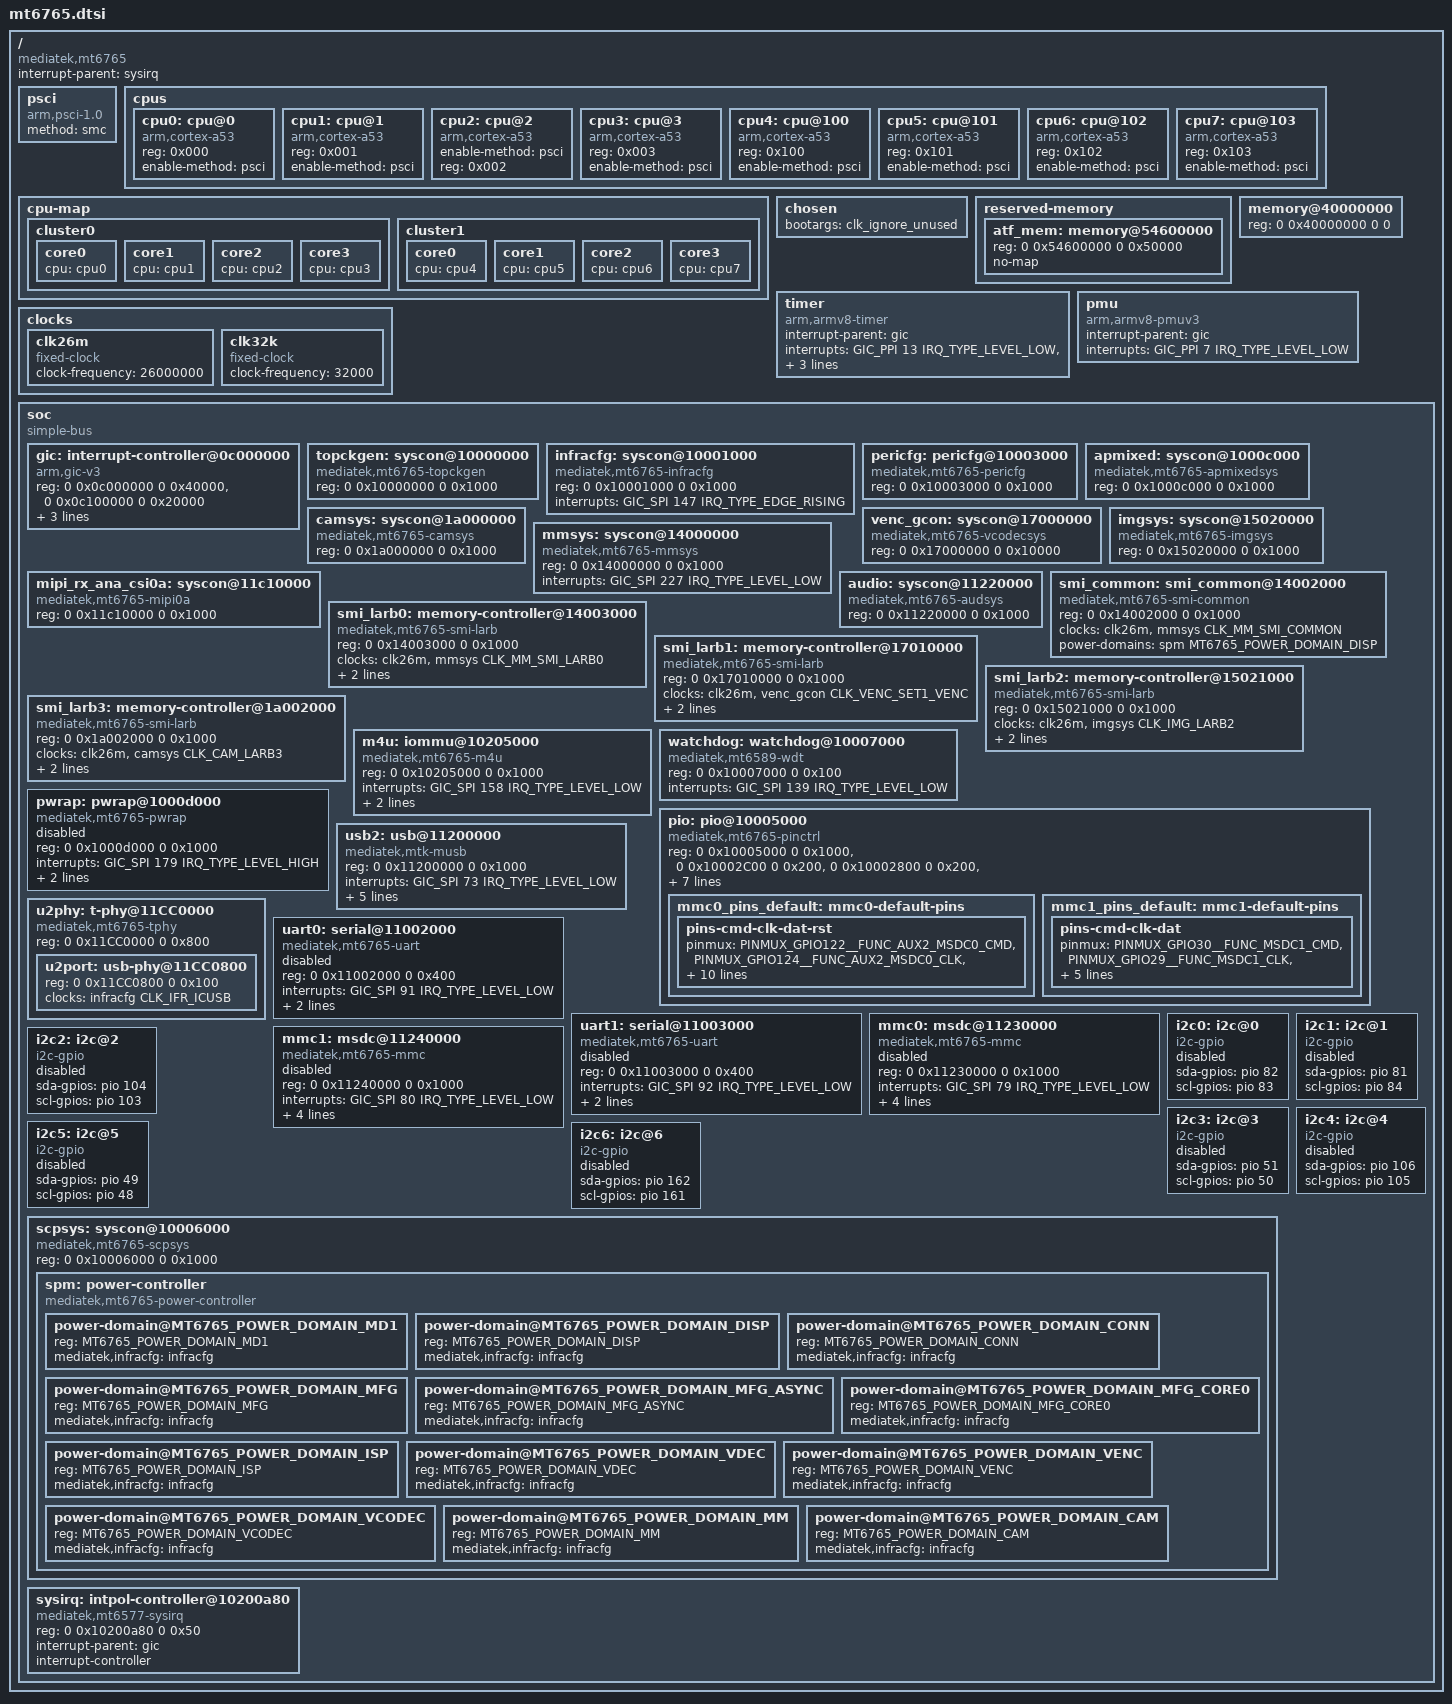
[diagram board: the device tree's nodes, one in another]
// SPDX-License-Identifier: GPL-2.0
/*
 * Copyright (c) 2023 Arseniy Velikanov <adomerlee@gmail.com>
 */

#include <dt-bindings/interrupt-controller/irq.h>
#include <dt-bindings/interrupt-controller/arm-gic.h>
#include <dt-bindings/clock/mt6765-clk.h>
#include <dt-bindings/gpio/gpio.h>
#include <dt-bindings/phy/phy.h>
#include <dt-bindings/power/mt6765-power.h>
#include <dt-bindings/pinctrl/mediatek,mt6765-pinfunc.h>

/ {
    compatible = "mediatek,mt6765";
    interrupt-parent = <&sysirq>;
    #address-cells = <2>;
    #size-cells = <2>;

    psci {
        compatible = "arm,psci-1.0";
        method = "smc";
    };

    cpus {
        #address-cells = <1>;
        #size-cells = <0>;

        cpu0: cpu@0 {
            device_type = "cpu";
            compatible = "arm,cortex-a53";
	        reg = <0x000>;
            enable-method = "psci";
        };

        cpu1: cpu@1 {
            device_type = "cpu";
            compatible = "arm,cortex-a53";
	        reg = <0x001>;
            enable-method = "psci";
        };

        cpu2: cpu@2 {
            device_type = "cpu";
            compatible = "arm,cortex-a53";
            enable-method = "psci";
            reg = <0x002>;
        };

        cpu3: cpu@3 {
            device_type = "cpu";
            compatible = "arm,cortex-a53";
	        reg = <0x003>;
            enable-method = "psci";
        };

        cpu4: cpu@100 {
            device_type = "cpu";
            compatible = "arm,cortex-a53";
	        reg = <0x100>;
            enable-method = "psci";
        };

        cpu5: cpu@101 {
            device_type = "cpu";
            compatible = "arm,cortex-a53";
	        reg = <0x101>;
            enable-method = "psci";
        };

        cpu6: cpu@102 {
            device_type = "cpu";
            compatible = "arm,cortex-a53";
	        reg = <0x102>;
            enable-method = "psci";
        };

        cpu7: cpu@103 {
            device_type = "cpu";
            compatible = "arm,cortex-a53";
	        reg = <0x103>;
            enable-method = "psci";
        };
    };

    cpu-map {
        cluster0 {
            core0 {
                cpu = <&cpu0>;
            };
            core1 {
                cpu = <&cpu1>;
            };
            core2 {
                cpu = <&cpu2>;
            };
            core3 {
                cpu = <&cpu3>;
            };
        };

        cluster1 {
            core0 {
                cpu = <&cpu4>;
            };
            core1 {
                cpu = <&cpu5>;
            };
            core2 {
                cpu = <&cpu6>;
            };
            core3 {
                cpu = <&cpu7>;
            };
        };
    };

    chosen {
        #address-cells = <2>;
        #size-cells = <2>;
        ranges;

        /*
         * FIXME: drop clk_ignore_unused, keeps getting watchdog rebooted without it for now!
         */
        bootargs = "clk_ignore_unused";
    };

    reserved-memory {
        #address-cells = <2>;
        #size-cells = <2>;
        ranges;

        atf_mem: memory@54600000 {
            reg = <0 0x54600000 0 0x50000>;
            no-map;
        };
    };

    memory@40000000 {
        device_type = "memory";
        /* We expect the bootloader to fill in the reg */
        reg = <0 0x40000000 0 0>;
    };

    timer {
        compatible = "arm,armv8-timer";
        interrupt-parent = <&gic>;
        interrupts = <GIC_PPI 13 IRQ_TYPE_LEVEL_LOW>,
                     <GIC_PPI 14 IRQ_TYPE_LEVEL_LOW>,
                     <GIC_PPI 11 IRQ_TYPE_LEVEL_LOW>,
                     <GIC_PPI 10 IRQ_TYPE_LEVEL_LOW>;
    };

    pmu {
        compatible = "arm,armv8-pmuv3";
        interrupt-parent = <&gic>;
        interrupts = <GIC_PPI 7 IRQ_TYPE_LEVEL_LOW>;
    };

    clocks {
        clk26m: clk26m {
            compatible = "fixed-clock";
            #clock-cells = <0>;
            clock-frequency = <26000000>;
        };

        clk32k: clk32k {
            compatible = "fixed-clock";
            #clock-cells = <0>;
            clock-frequency = <32000>;
        };
    };

    soc {
        #address-cells = <2>;
        #size-cells = <2>;
        compatible = "simple-bus";
        ranges;

        gic: interrupt-controller@0c000000 {
            compatible = "arm,gic-v3";
            reg = <0 0x0c000000 0 0x40000>,  /* GICD */
                  <0 0x0c100000 0 0x20000>;  /* GICR */
            #interrupt-cells = <3>;
            interrupt-parent = <&gic>;
            interrupts = <GIC_PPI 9 IRQ_TYPE_LEVEL_HIGH>;
            interrupt-controller;
        };

        topckgen: syscon@10000000 {
            compatible = "mediatek,mt6765-topckgen", "syscon";
            reg = <0 0x10000000 0 0x1000>;
            #clock-cells = <1>;
        };

        infracfg: syscon@10001000 {
            compatible = "mediatek,mt6765-infracfg", "syscon";
            reg = <0 0x10001000 0 0x1000>;
            interrupts = <GIC_SPI 147 IRQ_TYPE_EDGE_RISING>;
            #clock-cells = <1>;
        };

        pericfg: pericfg@10003000 {
            compatible = "mediatek,mt6765-pericfg", "syscon";
            reg = <0 0x10003000 0 0x1000>;
        };

        apmixed: syscon@1000c000 {
            compatible = "mediatek,mt6765-apmixedsys", "syscon";
            reg = <0 0x1000c000 0 0x1000>;
            #clock-cells = <1>;
        };

        camsys: syscon@1a000000  {
            compatible = "mediatek,mt6765-camsys", "syscon";
            reg = <0 0x1a000000 0 0x1000>;
            #clock-cells = <1>;
        };

        venc_gcon: syscon@17000000 {
            compatible = "mediatek,mt6765-vcodecsys", "syscon";
            reg = <0 0x17000000 0 0x10000>;
            #clock-cells = <1>;
        };

        imgsys: syscon@15020000 {
            compatible = "mediatek,mt6765-imgsys", "syscon";
            reg = <0 0x15020000 0 0x1000>;
            #clock-cells = <1>;
        };

        mmsys: syscon@14000000 {
            compatible = "mediatek,mt6765-mmsys", "syscon";
            reg = <0 0x14000000 0 0x1000>;
            interrupts = <GIC_SPI 227 IRQ_TYPE_LEVEL_LOW>;
            #clock-cells = <1>;
        };

        mipi_rx_ana_csi0a: syscon@11c10000 {
            compatible = "mediatek,mt6765-mipi0a", "syscon";
            reg = <0 0x11c10000 0 0x1000>;
            #clock-cells = <1>;
        };

        audio: syscon@11220000 {
            compatible = "mediatek,mt6765-audsys", "syscon";
            reg = <0 0x11220000 0 0x1000>;
            #clock-cells = <1>;
        };

        smi_common: smi_common@14002000 {
            compatible = "mediatek,mt6765-smi-common";
            reg = <0 0x14002000 0 0x1000>;
            clocks = <&clk26m>,
                     <&mmsys CLK_MM_SMI_COMMON>;
            clock-names = "apb", "smi";

            power-domains = <&spm MT6765_POWER_DOMAIN_DISP>;

        };

        smi_larb0: memory-controller@14003000 {
            compatible = "mediatek,mt6765-smi-larb";
            reg = <0 0x14003000 0 0x1000>;

            clocks = <&clk26m>,
                     <&mmsys CLK_MM_SMI_LARB0>;
            clock-names = "apb", "smi";

            power-domains = <&spm MT6765_POWER_DOMAIN_DISP>;

            mediatek,smi = <&smi_common>;
        };

        smi_larb1: memory-controller@17010000 {
            compatible = "mediatek,mt6765-smi-larb";
            reg = <0 0x17010000 0 0x1000>;

            clocks = <&clk26m>,
                     <&venc_gcon CLK_VENC_SET1_VENC>;
            clock-names = "apb", "smi";

            power-domains = <&spm MT6765_POWER_DOMAIN_VCODEC>;

            mediatek,smi = <&smi_common>;
        };

        smi_larb2: memory-controller@15021000 {
            compatible = "mediatek,mt6765-smi-larb";
            reg = <0 0x15021000 0 0x1000>;

            clocks = <&clk26m>,
                     <&imgsys CLK_IMG_LARB2>;
            clock-names = "apb", "smi";

            power-domains = <&spm MT6765_POWER_DOMAIN_ISP>;

            mediatek,smi = <&smi_common>;
        };

        smi_larb3: memory-controller@1a002000 {
            compatible = "mediatek,mt6765-smi-larb";
            reg = <0 0x1a002000 0 0x1000>;

            clocks = <&clk26m>,
                     <&camsys CLK_CAM_LARB3>;
            clock-names = "apb", "smi";

            power-domains = <&spm MT6765_POWER_DOMAIN_CAM>;

            mediatek,smi = <&smi_common>;
        };

        m4u: iommu@10205000 {
            compatible = "mediatek,mt6765-m4u";
            reg = <0 0x10205000 0 0x1000>;

            interrupts = <GIC_SPI 158 IRQ_TYPE_LEVEL_LOW>;

            mediatek,larbs = <&smi_larb0>, <&smi_larb1>,
                             <&smi_larb2>, <&smi_larb3>;

            #iommu-cells = <1>;
        };

        // TODO: Add reset support
        watchdog: watchdog@10007000 {
            compatible = "mediatek,mt6589-wdt";
            reg = <0 0x10007000 0 0x100>;
            interrupts = <GIC_SPI 139 IRQ_TYPE_LEVEL_LOW>;
        };

        // NOTE: downstream uses different iocfg naming
        pio: pio@10005000 {
            compatible = "mediatek,mt6765-pinctrl";
            reg = <0 0x10005000 0 0x1000>,
                  <0 0x10002C00 0 0x200>,
                  <0 0x10002800 0 0x200>,
                  <0 0x10002A00 0 0x200>,
                  <0 0x10002000 0 0x200>,
                  <0 0x10002200 0 0x200>,
                  <0 0x10002400 0 0x200>,
                  <0 0x10002600 0 0x200>,
                  <0 0x1000b000 0 0x1000>;
            reg-names = "iocfg0", /* pinctrl driver use gpio base as iocfg (???) */
                        "iocfg1",
                        "iocfg2",
                        "iocfg3",
                        "iocfg4",
                        "iocfg5",
                        "iocfg6",
                        "iocfg7",
                        "eint";
            gpio-controller;
            #gpio-cells = <2>;
            gpio-ranges = <&pio 0 0 179>;
            interrupt-controller;
            #interrupt-cells = <2>;
            interrupts = <GIC_SPI 171 IRQ_TYPE_LEVEL_HIGH>;

            mmc0_pins_default: mmc0-default-pins {
                pins-cmd-clk-dat-rst {
                    pinmux = <PINMUX_GPIO122__FUNC_AUX2_MSDC0_CMD>,
                             <PINMUX_GPIO124__FUNC_AUX2_MSDC0_CLK>,
                             <PINMUX_GPIO129__FUNC_MSDC0_DAT0>,
                             <PINMUX_GPIO127__FUNC_MSDC0_DAT1>,
                             <PINMUX_GPIO126__FUNC_MSDC0_DAT2>,
                             <PINMUX_GPIO132__FUNC_AUX2_MSDC0_DAT3>,
                             <PINMUX_GPIO123__FUNC_MSDC0_DAT4>,
                             <PINMUX_GPIO125__FUNC_MSDC0_DAT5>,
                             <PINMUX_GPIO128__FUNC_MSDC0_DAT6>,
                             <PINMUX_GPIO130__FUNC_AUX2_MSDC0_DAT7>,
                             <PINMUX_GPIO133__FUNC_AUX2_MSDC0_RSTB>;
                    drive-strength = <3>;
                };
            };

            mmc1_pins_default: mmc1-default-pins {
                pins-cmd-clk-dat {
                    pinmux = <PINMUX_GPIO30__FUNC_MSDC1_CMD>,
                             <PINMUX_GPIO29__FUNC_MSDC1_CLK>,
                             <PINMUX_GPIO32__FUNC_MSDC1_DAT0>,
                             <PINMUX_GPIO34__FUNC_MSDC1_DAT1>,
                             <PINMUX_GPIO33__FUNC_MSDC1_DAT2>,
                             <PINMUX_GPIO31__FUNC_MSDC1_DAT3>;
                    drive-strength = <3>;
                };
            };
        };

        pwrap: pwrap@1000d000 {
            compatible = "mediatek,mt6765-pwrap";
            reg = <0 0x1000d000 0 0x1000>;
            reg-names = "pwrap";
            interrupts = <GIC_SPI 179 IRQ_TYPE_LEVEL_HIGH>;
            clocks = <&infracfg CLK_IFR_PMIC_AP>,
                     <&topckgen CLK_TOP_CLK26M>;
            clock-names = "wrap", "spi";
            status = "disabled";
        };

        usb2: usb@11200000 {
            compatible = "mediatek,mtk-musb";
            reg = <0 0x11200000 0 0x1000>;
            interrupts = <GIC_SPI 73 IRQ_TYPE_LEVEL_LOW>;
            interrupt-names = "mc";
            clocks = <&infracfg CLK_IFR_ICUSB>,
                     <&topckgen CLK_TOP_USB_TOP_SEL>,
                     <&topckgen CLK_TOP_UNIVPLL3_D4>;
            clock-names = "main", "mcu", "univpll";
            phys = <&u2port PHY_TYPE_USB2>;
            dr_mode = "peripheral";
        };

        u2phy: t-phy@11CC0000 {
            compatible = "mediatek,mt6765-tphy",
                         "mediatek,generic-tphy-v1";
            reg = <0 0x11CC0000 0 0x800>;
            #address-cells = <2>;
            #size-cells = <2>;
            ranges;

            u2port: usb-phy@11CC0800 {
                reg = <0 0x11CC0800 0 0x100>;
                clocks = <&infracfg CLK_IFR_ICUSB>;
                clock-names = "ref";
                #phy-cells = <1>;
            };
        };

        uart0: serial@11002000 {
            compatible = "mediatek,mt6765-uart",
                         "mediatek,mt6577-uart";
            reg = <0 0x11002000 0 0x400>;
            interrupts = <GIC_SPI 91 IRQ_TYPE_LEVEL_LOW>;
            clocks = <&infracfg CLK_IFR_UART0>,
                     <&infracfg CLK_IFR_AP_DMA>;
            clock-names = "baud", "bus";
            status = "disabled";
        };

        uart1: serial@11003000 {
            compatible = "mediatek,mt6765-uart",
                         "mediatek,mt6577-uart";
            reg = <0 0x11003000 0 0x400>;
            interrupts = <GIC_SPI 92 IRQ_TYPE_LEVEL_LOW>;
            clocks = <&infracfg CLK_IFR_UART1>,
                     <&infracfg CLK_IFR_AP_DMA>;
            clock-names = "baud", "bus";
            status = "disabled";
        };


        mmc0: msdc@11230000 {
            compatible = "mediatek,mt6765-mmc";
            reg = <0 0x11230000 0 0x1000>;
            interrupts = <GIC_SPI 79 IRQ_TYPE_LEVEL_LOW>;
            clocks = <&infracfg CLK_IFR_MSDC0_SRC>,
                     <&infracfg CLK_IFR_MSDC0>;
            clock-names = "source", "hclk";
            pinctrl-0 = <&mmc0_pins_default>;
            pinctrl-1 = <&mmc0_pins_default>;
            pinctrl-names = "default", "state_uhs";
            status = "disabled";
        };

        mmc1: msdc@11240000 {
            compatible = "mediatek,mt6765-mmc";
            reg = <0 0x11240000 0 0x1000>;
            interrupts = <GIC_SPI 80 IRQ_TYPE_LEVEL_LOW>;
            clocks = <&infracfg CLK_IFR_MSDC1_SRC>,
                    <&infracfg CLK_IFR_MSDC1>;
            clock-names = "source", "hclk";
            pinctrl-0 = <&mmc1_pins_default>;
            pinctrl-1 = <&mmc1_pins_default>;
            pinctrl-names = "default", "state_uhs";
            status = "disabled";
        };

        // TODO: Use hardware i2c controller
        i2c0: i2c@0 {
            compatible = "i2c-gpio";
            sda-gpios = <&pio 82 (GPIO_ACTIVE_HIGH|GPIO_OPEN_DRAIN)>;
            scl-gpios = <&pio 83 (GPIO_ACTIVE_HIGH|GPIO_OPEN_DRAIN)>;
            status = "disabled";
        };

        i2c1: i2c@1 {
            compatible = "i2c-gpio";
            sda-gpios = <&pio 81 (GPIO_ACTIVE_HIGH|GPIO_OPEN_DRAIN)>;
            scl-gpios = <&pio 84 (GPIO_ACTIVE_HIGH|GPIO_OPEN_DRAIN)>;
            status = "disabled";
        };

        i2c2: i2c@2 {
            compatible = "i2c-gpio";
            sda-gpios = <&pio 104 (GPIO_ACTIVE_HIGH|GPIO_OPEN_DRAIN)>;
            scl-gpios = <&pio 103 (GPIO_ACTIVE_HIGH|GPIO_OPEN_DRAIN)>;
            status = "disabled";
        };

        i2c3: i2c@3 {
            compatible = "i2c-gpio";
            sda-gpios = <&pio 51 (GPIO_ACTIVE_HIGH|GPIO_OPEN_DRAIN)>;
            scl-gpios = <&pio 50 (GPIO_ACTIVE_HIGH|GPIO_OPEN_DRAIN)>;
            status = "disabled";
        };

        i2c4: i2c@4 {
            compatible = "i2c-gpio";
            sda-gpios = <&pio 106 (GPIO_ACTIVE_HIGH|GPIO_OPEN_DRAIN)>;
            scl-gpios = <&pio 105 (GPIO_ACTIVE_HIGH|GPIO_OPEN_DRAIN)>;
            status = "disabled";
        };

        i2c5: i2c@5 {
            compatible = "i2c-gpio";
            sda-gpios = <&pio 49 (GPIO_ACTIVE_HIGH|GPIO_OPEN_DRAIN)>;
            scl-gpios = <&pio 48 (GPIO_ACTIVE_HIGH|GPIO_OPEN_DRAIN)>;
            status = "disabled";
        };

        i2c6: i2c@6 {
            compatible = "i2c-gpio";
            sda-gpios = <&pio 162 (GPIO_ACTIVE_HIGH|GPIO_OPEN_DRAIN)>;
            scl-gpios = <&pio 161 (GPIO_ACTIVE_HIGH|GPIO_OPEN_DRAIN)>;
            status = "disabled";
        };

        scpsys: syscon@10006000 {
            compatible = "mediatek,mt6765-scpsys", "syscon", "simple-mfd";
            reg = <0 0x10006000 0 0x1000>;

            spm: power-controller {
                compatible = "mediatek,mt6765-power-controller";
                #address-cells = <1>;
                #size-cells = <0>;
                #power-domain-cells = <1>;

                power-domain@MT6765_POWER_DOMAIN_MD1 {
                    reg = <MT6765_POWER_DOMAIN_MD1>;
                    #power-domain-cells = <0>;
                    mediatek,infracfg = <&infracfg>;
                };

                power-domain@MT6765_POWER_DOMAIN_DISP {
                    reg = <MT6765_POWER_DOMAIN_DISP>;
                    #power-domain-cells = <0>;
                    mediatek,infracfg = <&infracfg>;
                };

                power-domain@MT6765_POWER_DOMAIN_CONN {
                    reg = <MT6765_POWER_DOMAIN_CONN>;
                    #power-domain-cells = <0>;
                    mediatek,infracfg = <&infracfg>;
                };

                power-domain@MT6765_POWER_DOMAIN_MFG {
                    reg = <MT6765_POWER_DOMAIN_MFG>;
                    #power-domain-cells = <0>;
                    mediatek,infracfg = <&infracfg>;
                };

                power-domain@MT6765_POWER_DOMAIN_MFG_ASYNC {
                    reg = <MT6765_POWER_DOMAIN_MFG_ASYNC>;
                    #power-domain-cells = <0>;
                    mediatek,infracfg = <&infracfg>;
                };

                power-domain@MT6765_POWER_DOMAIN_MFG_CORE0 {
                    reg = <MT6765_POWER_DOMAIN_MFG_CORE0>;
                    #power-domain-cells = <0>;
                    mediatek,infracfg = <&infracfg>;
                };

                power-domain@MT6765_POWER_DOMAIN_ISP {
                    reg = <MT6765_POWER_DOMAIN_ISP>;
                    #power-domain-cells = <0>;
                    mediatek,infracfg = <&infracfg>;
                };

                power-domain@MT6765_POWER_DOMAIN_VDEC {
                    reg = <MT6765_POWER_DOMAIN_VDEC>;
                    #power-domain-cells = <0>;
                    mediatek,infracfg = <&infracfg>;
                };

                power-domain@MT6765_POWER_DOMAIN_VENC {
                    reg = <MT6765_POWER_DOMAIN_VENC>;
                    #power-domain-cells = <0>;
                    mediatek,infracfg = <&infracfg>;
                };

                power-domain@MT6765_POWER_DOMAIN_VCODEC {
                    reg = <MT6765_POWER_DOMAIN_VCODEC>;
                    #power-domain-cells = <0>;
                    mediatek,infracfg = <&infracfg>;
                };

                power-domain@MT6765_POWER_DOMAIN_MM {
                    reg = <MT6765_POWER_DOMAIN_MM>;
                    #power-domain-cells = <0>;
                    mediatek,infracfg = <&infracfg>;
                };

                power-domain@MT6765_POWER_DOMAIN_CAM {
                    reg = <MT6765_POWER_DOMAIN_CAM>;
                    #power-domain-cells = <0>;
                    mediatek,infracfg = <&infracfg>;
                };
            };
        };

        sysirq: intpol-controller@10200a80 {
            compatible = "mediatek,mt6577-sysirq";
            reg = <0 0x10200a80 0 0x50>; /* INTPOL */
            #interrupt-cells = <3>;
            interrupt-parent = <&gic>;
            interrupt-controller;
        };
    };
};
